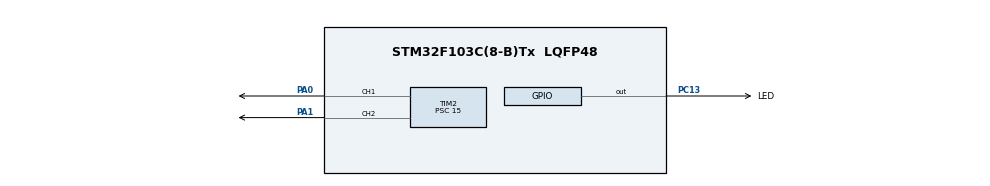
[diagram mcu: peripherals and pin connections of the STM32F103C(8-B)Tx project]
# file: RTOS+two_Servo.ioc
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FREERTOS.Tasks01=servo01,24,128,StartServoTask01,Default,NULL,Dynamic,NULL,NULL;servo02,8,128,StartServo02,Default,NULL,Dynamic,NULL,NULL
Mcu.Family=STM32F1
Mcu.Name=STM32F103C(8-B)Tx
Mcu.Package=LQFP48
NVIC.PriorityGroup=NVIC_PRIORITYGROUP_4
NVIC.TIM4_IRQn=true\:15\:0\:false\:false\:true\:false\:false\:true
NVIC.TimeBase=TIM4_IRQn
NVIC.TimeBaseIP=TIM4
PA0-WKUP.Signal=S_TIM2_CH1_ETR
PA1.Signal=S_TIM2_CH2
PA13.Mode=Serial_Wire
PA13.Signal=SYS_JTMS-SWDIO
PA14.Mode=Serial_Wire
PA14.Signal=SYS_JTCK-SWCLK
PC13-TAMPER-RTC.GPIO_Label=LED
PC13-TAMPER-RTC.Signal=GPIO_Output
PD0-OSC_IN.Mode=HSE-External-Oscillator
PD0-OSC_IN.Signal=RCC_OSC_IN
PD1-OSC_OUT.Mode=HSE-External-Oscillator
PD1-OSC_OUT.Signal=RCC_OSC_OUT
ProjectManager.HeapSize=0x200
ProjectManager.StackSize=0x400
ProjectManager.TargetToolchain=Makefile
RCC.APB1Freq_Value=8000000
RCC.APB2Freq_Value=8000000
SH.S_TIM2_CH1_ETR.0=TIM2_CH1,PWM Generation1 CH1
SH.S_TIM2_CH2.0=TIM2_CH2,PWM Generation2 CH2
TIM2.Channel-PWM\ Generation1\ CH1=TIM_CHANNEL_1
TIM2.Channel-PWM\ Generation2\ CH2=TIM_CHANNEL_2
TIM2.Period=9999
TIM2.Prescaler=15
VP_FREERTOS_VS_CMSIS_V2.Mode=CMSIS_V2
VP_SYS_VS_tim4.Mode=TIM4
VP_TIM2_VS_ClockSourceINT.Mode=Internal
board=custom

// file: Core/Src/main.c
/* USER CODE BEGIN Header */
/**
  ******************************************************************************
  * @file           : main.c
  * @brief          : Main program body
  ******************************************************************************
  * @attention
  *
  * <h2><center>&copy; Copyright (c) 2021 STMicroelectronics.
  * All rights reserved.</center></h2>
  *
  * This software component is licensed by ST under Ultimate Liberty license
  * SLA0044, the "License"; You may not use this file except in compliance with
  * the License. You may obtain a copy of the License at:
  *                             www.st.com/SLA0044
  *
  ******************************************************************************
  */
/* USER CODE END Header */
#include "main.h"
#include "cmsis_os.h"

TIM_HandleTypeDef htim2;

/* Definitions for servo01 */
osThreadId_t servo01Handle;
const osThreadAttr_t servo01_attributes = {
  .name = "servo01",
  .stack_size = 128 * 4,
  .priority = (osPriority_t) osPriorityNormal,
};
/* Definitions for servo02 */
osThreadId_t servo02Handle;
const osThreadAttr_t servo02_attributes = {
  .name = "servo02",
  .stack_size = 128 * 4,
  .priority = (osPriority_t) osPriorityLow,
};

void SystemClock_Config(void);
static void MX_GPIO_Init(void);
static void MX_TIM2_Init(void);
void StartServoTask01(void *argument);
void StartServo02(void *argument);

int main(void)
{

  /* MCU Configuration--------------------------------------------------------*/

  /* Reset of all peripherals, Initializes the Flash interface and the Systick. */
  HAL_Init();

  /* Configure the system clock */
  SystemClock_Config();

  /* Initialize all configured peripherals */
  MX_GPIO_Init();
  MX_TIM2_Init();
  /* USER CODE BEGIN 2 */
  HAL_TIM_PWM_Start(&htim2, TIM_CHANNEL_1);
  HAL_TIM_PWM_Start(&htim2, TIM_CHANNEL_2);
  /* USER CODE END 2 */

  /* Init scheduler */
  osKernelInitialize();

  /* Create the thread(s) */
  /* creation of servo01 */
  servo01Handle = osThreadNew(StartServoTask01, NULL, &servo01_attributes);

  /* creation of servo02 */
  servo02Handle = osThreadNew(StartServo02, NULL, &servo02_attributes);

  /* Start scheduler */
  osKernelStart();

  /* We should never get here as control is now taken by the scheduler */
  /* Infinite loop */
  while (1)
  {

  }
}

void SystemClock_Config(void)
{
  RCC_OscInitTypeDef RCC_OscInitStruct = {0};
  RCC_ClkInitTypeDef RCC_ClkInitStruct = {0};

  /** Initializes the RCC Oscillators according to the specified parameters
  * in the RCC_OscInitTypeDef structure.
  */
  RCC_OscInitStruct.OscillatorType = RCC_OSCILLATORTYPE_HSI;
  RCC_OscInitStruct.HSIState = RCC_HSI_ON;
  RCC_OscInitStruct.HSICalibrationValue = RCC_HSICALIBRATION_DEFAULT;
  RCC_OscInitStruct.PLL.PLLState = RCC_PLL_NONE;
  if (HAL_RCC_OscConfig(&RCC_OscInitStruct) != HAL_OK)
  {
    Error_Handler();
  }
  /** Initializes the CPU, AHB and APB buses clocks
  */
  RCC_ClkInitStruct.ClockType = RCC_CLOCKTYPE_HCLK|RCC_CLOCKTYPE_SYSCLK
                              |RCC_CLOCKTYPE_PCLK1|RCC_CLOCKTYPE_PCLK2;
  RCC_ClkInitStruct.SYSCLKSource = RCC_SYSCLKSOURCE_HSI;
  RCC_ClkInitStruct.AHBCLKDivider = RCC_SYSCLK_DIV1;
  RCC_ClkInitStruct.APB1CLKDivider = RCC_HCLK_DIV1;
  RCC_ClkInitStruct.APB2CLKDivider = RCC_HCLK_DIV1;

  if (HAL_RCC_ClockConfig(&RCC_ClkInitStruct, FLASH_LATENCY_0) != HAL_OK)
  {
    Error_Handler();
  }
}

static void MX_TIM2_Init(void)
{

  TIM_ClockConfigTypeDef sClockSourceConfig = {0};
  TIM_MasterConfigTypeDef sMasterConfig = {0};
  TIM_OC_InitTypeDef sConfigOC = {0};

  htim2.Instance = TIM2;
  htim2.Init.Prescaler = 15;
  htim2.Init.CounterMode = TIM_COUNTERMODE_UP;
  htim2.Init.Period = 9999;
  htim2.Init.ClockDivision = TIM_CLOCKDIVISION_DIV1;
  htim2.Init.AutoReloadPreload = TIM_AUTORELOAD_PRELOAD_DISABLE;
  if (HAL_TIM_Base_Init(&htim2) != HAL_OK)
  {
    Error_Handler();
  }
  sClockSourceConfig.ClockSource = TIM_CLOCKSOURCE_INTERNAL;
  if (HAL_TIM_ConfigClockSource(&htim2, &sClockSourceConfig) != HAL_OK)
  {
    Error_Handler();
  }
  if (HAL_TIM_PWM_Init(&htim2) != HAL_OK)
  {
    Error_Handler();
  }
  sMasterConfig.MasterOutputTrigger = TIM_TRGO_RESET;
  sMasterConfig.MasterSlaveMode = TIM_MASTERSLAVEMODE_DISABLE;
  if (HAL_TIMEx_MasterConfigSynchronization(&htim2, &sMasterConfig) != HAL_OK)
  {
    Error_Handler();
  }
  sConfigOC.OCMode = TIM_OCMODE_PWM1;
  sConfigOC.Pulse = 0;
  sConfigOC.OCPolarity = TIM_OCPOLARITY_HIGH;
  sConfigOC.OCFastMode = TIM_OCFAST_DISABLE;
  if (HAL_TIM_PWM_ConfigChannel(&htim2, &sConfigOC, TIM_CHANNEL_1) != HAL_OK)
  {
    Error_Handler();
  }
  if (HAL_TIM_PWM_ConfigChannel(&htim2, &sConfigOC, TIM_CHANNEL_2) != HAL_OK)
  {
    Error_Handler();
  }
  HAL_TIM_MspPostInit(&htim2);

}

static void MX_GPIO_Init(void)
{
  GPIO_InitTypeDef GPIO_InitStruct = {0};

  /* GPIO Ports Clock Enable */
  __HAL_RCC_GPIOC_CLK_ENABLE();
  __HAL_RCC_GPIOD_CLK_ENABLE();
  __HAL_RCC_GPIOA_CLK_ENABLE();

  /*Configure GPIO pin Output Level */
  HAL_GPIO_WritePin(LED_GPIO_Port, LED_Pin, GPIO_PIN_RESET);

  /*Configure GPIO pin : LED_Pin */
  GPIO_InitStruct.Pin = LED_Pin;
  GPIO_InitStruct.Mode = GPIO_MODE_OUTPUT_PP;
  GPIO_InitStruct.Pull = GPIO_NOPULL;
  GPIO_InitStruct.Speed = GPIO_SPEED_FREQ_LOW;
  HAL_GPIO_Init(LED_GPIO_Port, &GPIO_InitStruct);

}

void StartServoTask01(void *argument)
{
  /* USER CODE BEGIN 5 */
  /* Infinite loop */
  for(;;)
  {
    __HAL_TIM_SET_COMPARE(&htim2,TIM_CHANNEL_1, (uint16_t )250);
    osDelay(1000);
    // __HAL_TIM_SET_COMPARE(&htim2,TIM_CHANNEL_1, (uint16_t )750);
    // osDelay(1000);
    __HAL_TIM_SET_COMPARE(&htim2,TIM_CHANNEL_1, (uint16_t )1250);
    osDelay(1000);
  }
  /* USER CODE END 5 */
}

void StartServo02(void *argument)
{
  /* USER CODE BEGIN StartServo02 */
  /* Infinite loop */
  for(;;)
  {
    int y;
    for(y=250; y<1250; y=y+1)
    {
      __HAL_TIM_SET_COMPARE(&htim2,TIM_CHANNEL_2, y);
      osDelay(1);
    }
    osDelay(a);
    for(y=1250; y>250; y--)
    {
      __HAL_TIM_SET_COMPARE(&htim2,TIM_CHANNEL_2, y);
      osDelay(1);
    }
    osDelay(1000);
  }
  /* USER CODE END StartServo02 */
}

void HAL_TIM_PeriodElapsedCallback(TIM_HandleTypeDef *htim)
{
  if (htim->Instance == TIM4) {
    HAL_IncTick();
  }
}

void Error_Handler(void)
{
  __disable_irq();
  while (1)
  {
  }
}

/************************ (C) COPYRIGHT STMicroelectronics *****END OF FILE****/
